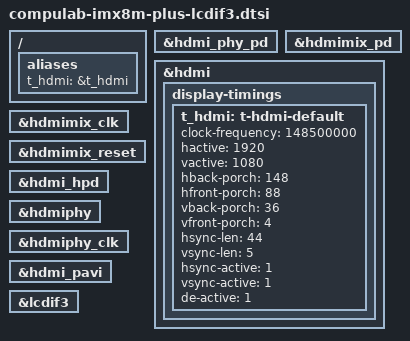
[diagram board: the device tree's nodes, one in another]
/ {
	aliases {
		t_hdmi = &t_hdmi;
	};

};

&hdmi_phy_pd {
	u-boot,dm-spl;
	status = "okay";
};

&hdmimix_pd {
	u-boot,dm-spl;
	status = "okay";
};

&hdmi {
    	u-boot,dm-spl;
	status = "okay";
	display-timings {
		t_hdmi: t-hdmi-default {
			/* m101nwwb by default */
			clock-frequency = <148500000>;
			hactive = <1920>;
			vactive = <1080>;
			hback-porch = <148>;
			hfront-porch = <88>;
			vback-porch = <36>;
			vfront-porch = <4>;
			hsync-len = <44>;
			vsync-len = <5>;
			hsync-active = <1>;
			vsync-active = <1>;
			de-active = <1>;
		};
	};
};

&hdmimix_clk {
	u-boot,dm-spl;
	status = "okay";
};

&hdmimix_reset {
	u-boot,dm-spl;
	status = "okay";
};

&hdmi_hpd {
	u-boot,dm-spl;
	status = "okay";
};

&hdmiphy {
	u-boot,dm-spl;
	status = "okay";
};

&hdmiphy_clk {
	u-boot,dm-spl;
	status = "okay";
};

&hdmi_pavi {
	u-boot,dm-spl;
	status = "okay";
};

&lcdif3 {
	u-boot,dm-spl;
	status = "okay";
};
